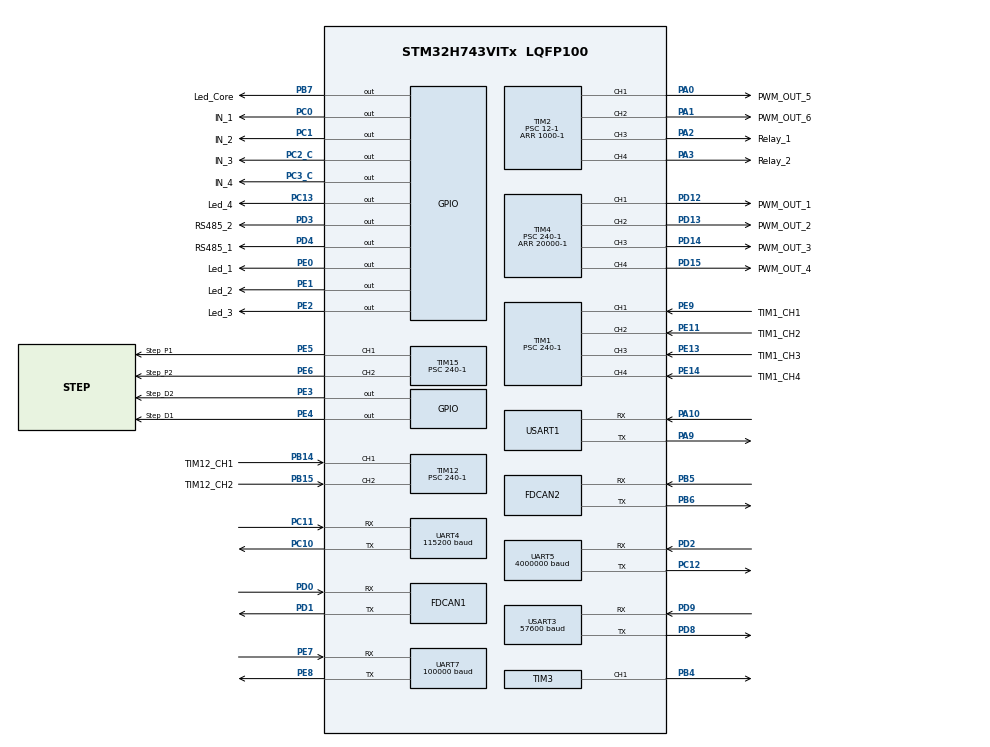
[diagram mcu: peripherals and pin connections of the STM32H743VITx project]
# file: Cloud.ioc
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CORTEX_M7.AccessPermission-Cortex_Memory_Protection_Unit_Region0_Settings=MPU_REGION_FULL_ACCESS
CORTEX_M7.BaseAddress-Cortex_Memory_Protection_Unit_Region0_Settings=0x24000000
CORTEX_M7.CPU_DCache=Enabled
CORTEX_M7.CPU_ICache=Enabled
CORTEX_M7.Enable-Cortex_Memory_Protection_Unit_Region0_Settings=MPU_REGION_ENABLE
CORTEX_M7.MPU_Control=MPU_PRIVILEGED_DEFAULT
CORTEX_M7.Size-Cortex_Memory_Protection_Unit_Region0_Settings=MPU_REGION_SIZE_256KB
CORTEX_M7.TypeExtField-Cortex_Memory_Protection_Unit_Region0_Settings=MPU_TEX_LEVEL1
Dma.Request0=UART4_RX
Dma.Request1=UART4_TX
Dma.Request2=UART5_RX
Dma.Request3=UART5_TX
Dma.Request4=USART3_RX
Dma.Request5=USART3_TX
Dma.Request6=TIM3_CH1
Dma.Request7=UART7_RX
Dma.Request8=USART1_RX
Dma.Request9=USART1_TX
Dma.TIM3_CH1.6.Direction=DMA_MEMORY_TO_PERIPH
Dma.TIM3_CH1.6.EventEnable=DISABLE
Dma.TIM3_CH1.6.FIFOMode=DMA_FIFOMODE_DISABLE
Dma.TIM3_CH1.6.Instance=DMA1_Stream6
Dma.TIM3_CH1.6.MemDataAlignment=DMA_MDATAALIGN_WORD
Dma.TIM3_CH1.6.MemInc=DMA_MINC_ENABLE
Dma.TIM3_CH1.6.Mode=DMA_NORMAL
Dma.TIM3_CH1.6.PeriphDataAlignment=DMA_PDATAALIGN_WORD
Dma.TIM3_CH1.6.PeriphInc=DMA_PINC_DISABLE
Dma.TIM3_CH1.6.Polarity=HAL_DMAMUX_REQ_GEN_RISING
Dma.TIM3_CH1.6.Priority=DMA_PRIORITY_LOW
Dma.TIM3_CH1.6.RequestNumber=1
Dma.TIM3_CH1.6.SignalID=NONE
Dma.TIM3_CH1.6.SyncEnable=DISABLE
Dma.TIM3_CH1.6.SyncPolarity=HAL_DMAMUX_SYNC_NO_EVENT
Dma.TIM3_CH1.6.SyncRequestNumber=1
Dma.TIM3_CH1.6.SyncSignalID=NONE
Dma.UART4_RX.0.Direction=DMA_PERIPH_TO_MEMORY
Dma.UART4_RX.0.EventEnable=DISABLE
Dma.UART4_RX.0.FIFOMode=DMA_FIFOMODE_DISABLE
Dma.UART4_RX.0.Instance=DMA1_Stream0
Dma.UART4_RX.0.MemDataAlignment=DMA_MDATAALIGN_BYTE
Dma.UART4_RX.0.MemInc=DMA_MINC_ENABLE
Dma.UART4_RX.0.Mode=DMA_CIRCULAR
Dma.UART4_RX.0.PeriphDataAlignment=DMA_PDATAALIGN_BYTE
Dma.UART4_RX.0.PeriphInc=DMA_PINC_DISABLE
Dma.UART4_RX.0.Polarity=HAL_DMAMUX_REQ_GEN_RISING
Dma.UART4_RX.0.Priority=DMA_PRIORITY_LOW
Dma.UART4_RX.0.RequestNumber=1
Dma.UART4_RX.0.SignalID=NONE
Dma.UART4_RX.0.SyncEnable=DISABLE
Dma.UART4_RX.0.SyncPolarity=HAL_DMAMUX_SYNC_NO_EVENT
Dma.UART4_RX.0.SyncRequestNumber=1
Dma.UART4_RX.0.SyncSignalID=NONE
Dma.UART4_TX.1.Direction=DMA_MEMORY_TO_PERIPH
Dma.UART4_TX.1.EventEnable=DISABLE
Dma.UART4_TX.1.FIFOMode=DMA_FIFOMODE_DISABLE
Dma.UART4_TX.1.Instance=DMA1_Stream1
Dma.UART4_TX.1.MemDataAlignment=DMA_MDATAALIGN_BYTE
Dma.UART4_TX.1.MemInc=DMA_MINC_ENABLE
Dma.UART4_TX.1.Mode=DMA_NORMAL
Dma.UART4_TX.1.PeriphDataAlignment=DMA_PDATAALIGN_BYTE
Dma.UART4_TX.1.PeriphInc=DMA_PINC_DISABLE
Dma.UART4_TX.1.Polarity=HAL_DMAMUX_REQ_GEN_RISING
Dma.UART4_TX.1.Priority=DMA_PRIORITY_LOW
Dma.UART4_TX.1.RequestNumber=1
Dma.UART4_TX.1.SignalID=NONE
Dma.UART4_TX.1.SyncEnable=DISABLE
Dma.UART4_TX.1.SyncPolarity=HAL_DMAMUX_SYNC_NO_EVENT
Dma.UART4_TX.1.SyncRequestNumber=1
Dma.UART4_TX.1.SyncSignalID=NONE
Dma.UART5_RX.2.Direction=DMA_PERIPH_TO_MEMORY
Dma.UART5_RX.2.EventEnable=DISABLE
Dma.UART5_RX.2.FIFOMode=DMA_FIFOMODE_DISABLE
Dma.UART5_RX.2.Instance=DMA1_Stream2
Dma.UART5_RX.2.MemDataAlignment=DMA_MDATAALIGN_BYTE
Dma.UART5_RX.2.MemInc=DMA_MINC_ENABLE
Dma.UART5_RX.2.Mode=DMA_CIRCULAR
Dma.UART5_RX.2.PeriphDataAlignment=DMA_PDATAALIGN_BYTE
Dma.UART5_RX.2.PeriphInc=DMA_PINC_DISABLE
Dma.UART5_RX.2.Polarity=HAL_DMAMUX_REQ_GEN_RISING
Dma.UART5_RX.2.Priority=DMA_PRIORITY_LOW
Dma.UART5_RX.2.RequestNumber=1
Dma.UART5_RX.2.SignalID=NONE
Dma.UART5_RX.2.SyncEnable=DISABLE
Dma.UART5_RX.2.SyncPolarity=HAL_DMAMUX_SYNC_NO_EVENT
Dma.UART5_RX.2.SyncRequestNumber=1
Dma.UART5_RX.2.SyncSignalID=NONE
Dma.UART5_TX.3.Direction=DMA_MEMORY_TO_PERIPH
Dma.UART5_TX.3.EventEnable=DISABLE
Dma.UART5_TX.3.FIFOMode=DMA_FIFOMODE_DISABLE
Dma.UART5_TX.3.Instance=DMA1_Stream3
Dma.UART5_TX.3.MemDataAlignment=DMA_MDATAALIGN_BYTE
Dma.UART5_TX.3.MemInc=DMA_MINC_ENABLE
Dma.UART5_TX.3.Mode=DMA_NORMAL
Dma.UART5_TX.3.PeriphDataAlignment=DMA_PDATAALIGN_BYTE
Dma.UART5_TX.3.PeriphInc=DMA_PINC_DISABLE
Dma.UART5_TX.3.Polarity=HAL_DMAMUX_REQ_GEN_RISING
Dma.UART5_TX.3.Priority=DMA_PRIORITY_LOW
Dma.UART5_TX.3.RequestNumber=1
Dma.UART5_TX.3.SignalID=NONE
Dma.UART5_TX.3.SyncEnable=DISABLE
Dma.UART5_TX.3.SyncPolarity=HAL_DMAMUX_SYNC_NO_EVENT
Dma.UART5_TX.3.SyncRequestNumber=1
Dma.UART5_TX.3.SyncSignalID=NONE
Dma.UART7_RX.7.Direction=DMA_PERIPH_TO_MEMORY
Dma.UART7_RX.7.EventEnable=DISABLE
Dma.UART7_RX.7.FIFOMode=DMA_FIFOMODE_DISABLE
Dma.UART7_RX.7.Instance=DMA1_Stream7
Dma.UART7_RX.7.MemDataAlignment=DMA_MDATAALIGN_BYTE
Dma.UART7_RX.7.MemInc=DMA_MINC_ENABLE
Dma.UART7_RX.7.Mode=DMA_CIRCULAR
Dma.UART7_RX.7.PeriphDataAlignment=DMA_PDATAALIGN_BYTE
Dma.UART7_RX.7.PeriphInc=DMA_PINC_DISABLE
Dma.UART7_RX.7.Polarity=HAL_DMAMUX_REQ_GEN_RISING
Dma.UART7_RX.7.Priority=DMA_PRIORITY_LOW
Dma.UART7_RX.7.RequestNumber=1
Dma.UART7_RX.7.SignalID=NONE
Dma.UART7_RX.7.SyncEnable=DISABLE
Dma.UART7_RX.7.SyncPolarity=HAL_DMAMUX_SYNC_NO_EVENT
Dma.UART7_RX.7.SyncRequestNumber=1
Dma.UART7_RX.7.SyncSignalID=NONE
Dma.USART1_RX.8.Direction=DMA_PERIPH_TO_MEMORY
Dma.USART1_RX.8.EventEnable=DISABLE
Dma.USART1_RX.8.FIFOMode=DMA_FIFOMODE_DISABLE
Dma.USART1_RX.8.Instance=DMA2_Stream0
Dma.USART1_RX.8.MemDataAlignment=DMA_MDATAALIGN_BYTE
Dma.USART1_RX.8.MemInc=DMA_MINC_ENABLE
Dma.USART1_RX.8.Mode=DMA_CIRCULAR
Dma.USART1_RX.8.PeriphDataAlignment=DMA_PDATAALIGN_BYTE
Dma.USART1_RX.8.PeriphInc=DMA_PINC_DISABLE
Dma.USART1_RX.8.Polarity=HAL_DMAMUX_REQ_GEN_RISING
Dma.USART1_RX.8.Priority=DMA_PRIORITY_LOW
Dma.USART1_RX.8.RequestNumber=1
Dma.USART1_RX.8.SignalID=NONE
Dma.USART1_RX.8.SyncEnable=DISABLE
Dma.USART1_RX.8.SyncPolarity=HAL_DMAMUX_SYNC_NO_EVENT
Dma.USART1_RX.8.SyncRequestNumber=1
Dma.USART1_RX.8.SyncSignalID=NONE
Dma.USART1_TX.9.Direction=DMA_MEMORY_TO_PERIPH
Dma.USART1_TX.9.EventEnable=DISABLE
Dma.USART1_TX.9.FIFOMode=DMA_FIFOMODE_DISABLE
Dma.USART1_TX.9.Instance=DMA2_Stream1
Dma.USART1_TX.9.MemDataAlignment=DMA_MDATAALIGN_BYTE
Dma.USART1_TX.9.MemInc=DMA_MINC_ENABLE
Dma.USART1_TX.9.Mode=DMA_NORMAL
Dma.USART1_TX.9.PeriphDataAlignment=DMA_PDATAALIGN_BYTE
Dma.USART1_TX.9.PeriphInc=DMA_PINC_DISABLE
Dma.USART1_TX.9.Polarity=HAL_DMAMUX_REQ_GEN_RISING
Dma.USART1_TX.9.Priority=DMA_PRIORITY_LOW
Dma.USART1_TX.9.RequestNumber=1
Dma.USART1_TX.9.SignalID=NONE
Dma.USART1_TX.9.SyncEnable=DISABLE
Dma.USART1_TX.9.SyncPolarity=HAL_DMAMUX_SYNC_NO_EVENT
Dma.USART1_TX.9.SyncRequestNumber=1
Dma.USART1_TX.9.SyncSignalID=NONE
Dma.USART3_RX.4.Direction=DMA_PERIPH_TO_MEMORY
Dma.USART3_RX.4.EventEnable=DISABLE
Dma.USART3_RX.4.FIFOMode=DMA_FIFOMODE_DISABLE
Dma.USART3_RX.4.Instance=DMA1_Stream4
Dma.USART3_RX.4.MemDataAlignment=DMA_MDATAALIGN_BYTE
Dma.USART3_RX.4.MemInc=DMA_MINC_ENABLE
Dma.USART3_RX.4.Mode=DMA_CIRCULAR
Dma.USART3_RX.4.PeriphDataAlignment=DMA_PDATAALIGN_BYTE
Dma.USART3_RX.4.PeriphInc=DMA_PINC_DISABLE
Dma.USART3_RX.4.Polarity=HAL_DMAMUX_REQ_GEN_RISING
Dma.USART3_RX.4.Priority=DMA_PRIORITY_LOW
Dma.USART3_RX.4.RequestNumber=1
Dma.USART3_RX.4.SignalID=NONE
Dma.USART3_RX.4.SyncEnable=DISABLE
Dma.USART3_RX.4.SyncPolarity=HAL_DMAMUX_SYNC_NO_EVENT
Dma.USART3_RX.4.SyncRequestNumber=1
Dma.USART3_RX.4.SyncSignalID=NONE
Dma.USART3_TX.5.Direction=DMA_MEMORY_TO_PERIPH
Dma.USART3_TX.5.EventEnable=DISABLE
Dma.USART3_TX.5.FIFOMode=DMA_FIFOMODE_DISABLE
Dma.USART3_TX.5.Instance=DMA1_Stream5
Dma.USART3_TX.5.MemDataAlignment=DMA_MDATAALIGN_BYTE
Dma.USART3_TX.5.MemInc=DMA_MINC_ENABLE
Dma.USART3_TX.5.Mode=DMA_NORMAL
Dma.USART3_TX.5.PeriphDataAlignment=DMA_PDATAALIGN_BYTE
Dma.USART3_TX.5.PeriphInc=DMA_PINC_DISABLE
Dma.USART3_TX.5.Polarity=HAL_DMAMUX_REQ_GEN_RISING
Dma.USART3_TX.5.Priority=DMA_PRIORITY_LOW
Dma.USART3_TX.5.RequestNumber=1
Dma.USART3_TX.5.SignalID=NONE
Dma.USART3_TX.5.SyncEnable=DISABLE
Dma.USART3_TX.5.SyncPolarity=HAL_DMAMUX_SYNC_NO_EVENT
Dma.USART3_TX.5.SyncRequestNumber=1
Dma.USART3_TX.5.SyncSignalID=NONE
FDCAN1.DataTimeSeg1=31
FDCAN1.DataTimeSeg2=8
FDCAN1.ExtFiltersNbr=32
FDCAN1.NominalSyncJumpWidth=2
FDCAN1.NominalTimeSeg1=31
FDCAN1.NominalTimeSeg2=8
FDCAN1.ProtocolException=ENABLE
FDCAN1.RxBuffersNbr=32
FDCAN1.RxFifo0ElmtsNbr=32
FDCAN1.StdFiltersNbr=32
FDCAN1.TxFifoQueueElmtsNbr=32
FDCAN2.DataTimeSeg1=31
FDCAN2.DataTimeSeg2=8
FDCAN2.ExtFiltersNbr=32
FDCAN2.MessageRAMOffset=1280
FDCAN2.NominalSyncJumpWidth=2
FDCAN2.NominalTimeSeg1=31
FDCAN2.NominalTimeSeg2=8
FDCAN2.ProtocolException=ENABLE
FDCAN2.RxBuffersNbr=32
FDCAN2.RxFifo1ElmtsNbr=32
FDCAN2.StdFiltersNbr=32
FDCAN2.TxFifoQueueElmtsNbr=32
Mcu.Family=STM32H7
Mcu.Name=STM32H743VITx
Mcu.Package=LQFP100
NVIC.DMA1_Stream0_IRQn=true\:4\:0\:true\:false\:true\:false\:true
NVIC.DMA1_Stream1_IRQn=true\:4\:0\:true\:false\:true\:false\:true
NVIC.DMA1_Stream2_IRQn=true\:4\:0\:true\:false\:true\:false\:true
NVIC.DMA1_Stream3_IRQn=true\:4\:0\:true\:false\:true\:false\:true
NVIC.DMA1_Stream4_IRQn=true\:4\:0\:true\:false\:true\:false\:true
NVIC.DMA1_Stream5_IRQn=true\:4\:0\:true\:false\:true\:false\:true
NVIC.DMA1_Stream6_IRQn=true\:5\:0\:true\:false\:true\:false\:true
NVIC.DMA1_Stream7_IRQn=true\:4\:0\:true\:false\:true\:false\:true
NVIC.DMA2_Stream0_IRQn=true\:0\:0\:false\:false\:true\:false\:true
NVIC.DMA2_Stream1_IRQn=true\:0\:0\:false\:false\:true\:false\:true
NVIC.FDCAN1_IT0_IRQn=true\:4\:0\:true\:false\:true\:true\:true
NVIC.FDCAN2_IT0_IRQn=true\:4\:0\:true\:false\:true\:true\:true
NVIC.PriorityGroup=NVIC_PRIORITYGROUP_4
NVIC.TIM1_CC_IRQn=true\:5\:0\:true\:false\:true\:true\:true
NVIC.TIM6_DAC_IRQn=true\:7\:0\:true\:false\:true\:true\:true
NVIC.TIM8_BRK_TIM12_IRQn=true\:6\:0\:true\:false\:true\:true\:true
NVIC.UART4_IRQn=true\:5\:0\:true\:false\:true\:true\:true
NVIC.UART5_IRQn=true\:5\:0\:true\:false\:true\:true\:true
NVIC.UART7_IRQn=true\:5\:0\:true\:false\:true\:true\:true
NVIC.USART1_IRQn=true\:5\:0\:true\:false\:true\:true\:true
NVIC.USART3_IRQn=true\:5\:0\:true\:false\:true\:true\:true
PA0.GPIO_Label=PWM_OUT_5
PA0.Signal=S_TIM2_CH1_ETR
PA1.GPIO_Label=PWM_OUT_6
PA1.Signal=S_TIM2_CH2
PA10.Mode=Asynchronous
PA10.Signal=USART1_RX
PA13\ (JTMS/SWDIO).Mode=Serial_Wire
PA13\ (JTMS/SWDIO).Signal=DEBUG_JTMS-SWDIO
PA14\ (JTCK/SWCLK).Mode=Serial_Wire
PA14\ (JTCK/SWCLK).Signal=DEBUG_JTCK-SWCLK
PA2.GPIO_Label=Relay_1
PA2.Signal=S_TIM2_CH3
PA3.GPIO_Label=Relay_2
PA3.Signal=S_TIM2_CH4
PA9.Mode=Asynchronous
PA9.Signal=USART1_TX
PB14.GPIO_Label=TIM12_CH1
PB14.Signal=S_TIM12_CH1
PB15.GPIO_Label=TIM12_CH2
PB15.Signal=S_TIM12_CH2
PB4\ (NJTRST).Signal=S_TIM3_CH1
PB5.Mode=FDCAN_Activate
PB5.Signal=FDCAN2_RX
PB6.Mode=FDCAN_Activate
PB6.Signal=FDCAN2_TX
PB7.GPIO_Label=Led_Core
PB7.Signal=GPIO_Output
PC0.GPIO_Label=IN_1
PC0.Signal=GPIO_Output
PC1.GPIO_Label=IN_2
PC1.Signal=GPIO_Output
PC10.Mode=Asynchronous
PC10.Signal=UART4_TX
PC11.Mode=Asynchronous
PC11.Signal=UART4_RX
PC12.Mode=Asynchronous
PC12.Signal=UART5_TX
PC13.GPIO_Label=Led_4
PC13.Signal=GPIO_Output
PC14-OSC32_IN\ (OSC32_IN).Mode=LSE-External-Oscillator
PC14-OSC32_IN\ (OSC32_IN).Signal=RCC_OSC32_IN
PC15-OSC32_OUT\ (OSC32_OUT).Mode=LSE-External-Oscillator
PC15-OSC32_OUT\ (OSC32_OUT).Signal=RCC_OSC32_OUT
PC2_C.GPIO_Label=IN_3
PC2_C.Signal=GPIO_Output
PC3_C.GPIO_Label=IN_4
PC3_C.Signal=GPIO_Output
PD0.Mode=FDCAN_Activate
PD0.Signal=FDCAN1_RX
PD1.Mode=FDCAN_Activate
PD1.Signal=FDCAN1_TX
PD12.GPIO_Label=PWM_OUT_1
PD12.Signal=S_TIM4_CH1
PD13.GPIO_Label=PWM_OUT_2
PD13.Signal=S_TIM4_CH2
PD14.GPIO_Label=PWM_OUT_3
PD14.Signal=S_TIM4_CH3
PD15.GPIO_Label=PWM_OUT_4
PD15.Signal=S_TIM4_CH4
PD2.Mode=Asynchronous
PD2.Signal=UART5_RX
PD3.GPIO_Label=RS485_2
PD3.PinState=GPIO_PIN_RESET
PD3.Signal=GPIO_Output
PD4.GPIO_Label=RS485_1
PD4.PinState=GPIO_PIN_RESET
PD4.Signal=GPIO_Output
PD8.Mode=Asynchronous
PD8.Signal=USART3_TX
PD9.Mode=Asynchronous
PD9.Signal=USART3_RX
PE0.GPIO_Label=Led_1
PE0.Signal=GPIO_Output
PE1.GPIO_Label=Led_2
PE1.Signal=GPIO_Output
PE11.GPIO_Label=TIM1_CH2
PE11.Signal=S_TIM1_CH2
PE13.GPIO_Label=TIM1_CH3
PE13.Signal=S_TIM1_CH3
PE14.GPIO_Label=TIM1_CH4
PE14.Signal=S_TIM1_CH4
PE2.GPIO_Label=Led_3
PE2.Signal=GPIO_Output
PE3.GPIO_Label=Step_D2
PE3.PinState=GPIO_PIN_RESET
PE3.Signal=GPIO_Output
PE4.GPIO_Label=Step_D1
PE4.PinState=GPIO_PIN_RESET
PE4.Signal=GPIO_Output
PE5.GPIO_Label=Step_P1
PE5.Signal=S_TIM15_CH1
PE6.GPIO_Label=Step_P2
PE6.Signal=S_TIM15_CH2
PE7.Mode=Asynchronous
PE7.Signal=UART7_RX
PE8.Mode=Asynchronous
PE8.Signal=UART7_TX
PE9.GPIO_Label=TIM1_CH1
PE9.Signal=S_TIM1_CH1
PH0-OSC_IN\ (PH0).Mode=HSE-External-Oscillator
PH0-OSC_IN\ (PH0).Signal=RCC_OSC_IN
PH1-OSC_OUT\ (PH1).Mode=HSE-External-Oscillator
PH1-OSC_OUT\ (PH1).Signal=RCC_OSC_OUT
ProjectManager.HeapSize=0x200
ProjectManager.StackSize=0x400
ProjectManager.TargetToolchain=MDK-ARM V5.32
RCC.ADCFreq_Value=480000000
RCC.APB1Freq_Value=120000000
RCC.APB2Freq_Value=120000000
RCC.APB3Freq_Value=120000000
RCC.APB4Freq_Value=120000000
RCC.CortexFreq_Value=480000000
RCC.D1PPRE=RCC_APB3_DIV2
RCC.D2PPRE1=RCC_APB1_DIV2
RCC.D2PPRE2=RCC_APB2_DIV2
RCC.D3PPRE=RCC_APB4_DIV2
RCC.DIVM1=2
RCC.DIVM2=2
RCC.DIVN1=240
RCC.DIVN2=240
RCC.DIVQ1=24
RCC.DIVQ2=24
RCC.HCLKFreq_Value=240000000
RCC.HPRE=RCC_HCLK_DIV2
RCC.HSE_VALUE=8000000
RCC.PLLFRACN=0
RCC.PLLSourceVirtual=RCC_PLLSOURCE_HSE
RCC.SYSCLKFreq_VALUE=480000000
RCC.SYSCLKSource=RCC_SYSCLKSOURCE_PLLCLK
RCC.USBFreq_Value=40000000
SH.S_TIM12_CH1.0=TIM12_CH1,Input_Capture1_from_TI1
SH.S_TIM12_CH2.0=TIM12_CH2,Input_Capture2_from_TI2
SH.S_TIM15_CH1.0=TIM15_CH1,PWM Generation1 CH1
SH.S_TIM15_CH2.0=TIM15_CH2,PWM Generation2 CH2
SH.S_TIM1_CH1.0=TIM1_CH1,Input_Capture1_from_TI1
SH.S_TIM1_CH2.0=TIM1_CH2,Input_Capture2_from_TI2
SH.S_TIM1_CH3.0=TIM1_CH3,Input_Capture3_from_TI3
SH.S_TIM1_CH4.0=TIM1_CH4,Input_Capture4_from_TI4
SH.S_TIM2_CH1_ETR.0=TIM2_CH1,PWM Generation1 CH1
SH.S_TIM2_CH2.0=TIM2_CH2,PWM Generation2 CH2
SH.S_TIM2_CH3.0=TIM2_CH3,PWM Generation3 CH3
SH.S_TIM2_CH4.0=TIM2_CH4,PWM Generation4 CH4
SH.S_TIM3_CH1.0=TIM3_CH1,PWM Generation1 CH1
SH.S_TIM4_CH1.0=TIM4_CH1,PWM Generation1 CH1
SH.S_TIM4_CH2.0=TIM4_CH2,PWM Generation2 CH2
SH.S_TIM4_CH3.0=TIM4_CH3,PWM Generation3 CH3
SH.S_TIM4_CH4.0=TIM4_CH4,PWM Generation4 CH4
TIM1.Channel-Input_Capture1_from_TI1=TIM_CHANNEL_1
TIM1.Channel-Input_Capture2_from_TI2=TIM_CHANNEL_2
TIM1.Channel-Input_Capture3_from_TI3=TIM_CHANNEL_3
TIM1.Channel-Input_Capture4_from_TI4=TIM_CHANNEL_4
TIM1.ICPolarity_CH1=TIM_INPUTCHANNELPOLARITY_BOTHEDGE
TIM1.ICPolarity_CH2=TIM_INPUTCHANNELPOLARITY_BOTHEDGE
TIM1.ICPolarity_CH3=TIM_INPUTCHANNELPOLARITY_BOTHEDGE
TIM1.ICPolarity_CH4=TIM_INPUTCHANNELPOLARITY_BOTHEDGE
TIM1.Prescaler=240-1
TIM12.Channel-Input_Capture1_from_TI1=TIM_CHANNEL_1
TIM12.Channel-Input_Capture2_from_TI2=TIM_CHANNEL_2
TIM12.ICPolarity_CH1=TIM_INPUTCHANNELPOLARITY_BOTHEDGE
TIM12.ICPolarity_CH2=TIM_INPUTCHANNELPOLARITY_BOTHEDGE
TIM12.Prescaler=240-1
TIM15.Channel-PWM\ Generation1\ CH1=TIM_CHANNEL_1
TIM15.Channel-PWM\ Generation2\ CH2=TIM_CHANNEL_2
TIM15.Period=10000-1
TIM15.Prescaler=240-1
TIM2.Channel-PWM\ Generation1\ CH1=TIM_CHANNEL_1
TIM2.Channel-PWM\ Generation2\ CH2=TIM_CHANNEL_2
TIM2.Channel-PWM\ Generation3\ CH3=TIM_CHANNEL_3
TIM2.Channel-PWM\ Generation4\ CH4=TIM_CHANNEL_4
TIM2.Period=1000-1
TIM2.Prescaler=12-1
TIM3.Channel-PWM\ Generation1\ CH1=TIM_CHANNEL_1
TIM3.Period=4-1
TIM3.Prescaler=80-1
TIM4.Channel-PWM\ Generation1\ CH1=TIM_CHANNEL_1
TIM4.Channel-PWM\ Generation2\ CH2=TIM_CHANNEL_2
TIM4.Channel-PWM\ Generation3\ CH3=TIM_CHANNEL_3
TIM4.Channel-PWM\ Generation4\ CH4=TIM_CHANNEL_4
TIM4.Period=20000-1
TIM4.Prescaler=240-1
TIM6.Period=1000-1
TIM6.Prescaler=240-1
UART4.BaudRate=115200
UART5.BaudRate=4000000
UART7.BaudRate=100000
UART7.Parity=PARITY_EVEN
UART7.StopBits=UART_STOPBITS_2
UART7.WordLength=WORDLENGTH_9B
USART1.VirtualMode-Asynchronous=VM_ASYNC
USART3.BaudRate=57600
USART3.VirtualMode-Asynchronous=VM_ASYNC
VP_TIM12_VS_ClockSourceINT.Mode=Internal
VP_TIM15_VS_ClockSourceINT.Mode=Internal
VP_TIM1_VS_ClockSourceINT.Mode=Internal
VP_TIM2_VS_ClockSourceINT.Mode=Internal
VP_TIM3_VS_ClockSourceINT.Mode=Internal
VP_TIM4_VS_ClockSourceINT.Mode=Internal
VP_TIM6_VS_ClockSourceINT.Mode=Enable_Timer
board=custom

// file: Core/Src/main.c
/* USER CODE BEGIN Header */
/**
  ******************************************************************************
  * @file           : main.c
  * @brief          : Main program body
  ******************************************************************************
  * @attention
  *
  * Copyright (c) 2025 STMicroelectronics.
  * All rights reserved.
  *
  * This software is licensed under terms that can be found in the LICENSE file
  * in the root directory of this software component.
  * If no LICENSE file comes with this software, it is provided AS-IS.
  *
  ******************************************************************************
  */
/* USER CODE END Header */
#include "main.h"
#include "dma.h"
#include "fdcan.h"
#include "tim.h"
#include "usart.h"
#include "gpio.h"

void SystemClock_Config(void);
static void MPU_Config(void);

int main(void)
{

  /* MPU Configuration--------------------------------------------------------*/
  MPU_Config();

  /* Enable I-Cache---------------------------------------------------------*/
  SCB_EnableICache();

  /* Enable D-Cache---------------------------------------------------------*/
  SCB_EnableDCache();

  /* MCU Configuration--------------------------------------------------------*/

  /* Reset of all peripherals, Initializes the Flash interface and the Systick. */
  HAL_Init();

  /* USER CODE BEGIN Init */

	HAL_Delay(1000);//�ȴ�1S��ϵͳ����   ��ɾ

  /* USER CODE END Init */

  /* Configure the system clock */
  SystemClock_Config();

  /* Initialize all configured peripherals */
  MX_GPIO_Init();
  MX_DMA_Init();
  MX_TIM1_Init();
  MX_TIM6_Init();
  MX_TIM12_Init();
  MX_TIM15_Init();
  MX_TIM2_Init();
  MX_TIM4_Init();
  MX_FDCAN1_Init();
  MX_UART4_Init();
  MX_FDCAN2_Init();
  MX_UART5_Init();
  MX_USART3_UART_Init();
  MX_TIM3_Init();
  MX_UART7_Init();
  MX_USART1_UART_Init();
  /* USER CODE BEGIN 2 */
   Mymain();

  /* USER CODE END 2 */

  /* Infinite loop */
  while (1)
  {

  }
}

void SystemClock_Config(void)
{
  RCC_OscInitTypeDef RCC_OscInitStruct = {0};
  RCC_ClkInitTypeDef RCC_ClkInitStruct = {0};

  /** Supply configuration update enable
  */
  HAL_PWREx_ConfigSupply(PWR_LDO_SUPPLY);
  /** Configure the main internal regulator output voltage
  */
  __HAL_PWR_VOLTAGESCALING_CONFIG(PWR_REGULATOR_VOLTAGE_SCALE0);

  while(!__HAL_PWR_GET_FLAG(PWR_FLAG_VOSRDY)) {}
  /** Initializes the RCC Oscillators according to the specified parameters
  * in the RCC_OscInitTypeDef structure.
  */
  RCC_OscInitStruct.OscillatorType = RCC_OSCILLATORTYPE_HSE;
  RCC_OscInitStruct.HSEState = RCC_HSE_ON;
  RCC_OscInitStruct.PLL.PLLState = RCC_PLL_ON;
  RCC_OscInitStruct.PLL.PLLSource = RCC_PLLSOURCE_HSE;
  RCC_OscInitStruct.PLL.PLLM = 2;
  RCC_OscInitStruct.PLL.PLLN = 240;
  RCC_OscInitStruct.PLL.PLLP = 2;
  RCC_OscInitStruct.PLL.PLLQ = 24;
  RCC_OscInitStruct.PLL.PLLR = 2;
  RCC_OscInitStruct.PLL.PLLRGE = RCC_PLL1VCIRANGE_2;
  RCC_OscInitStruct.PLL.PLLVCOSEL = RCC_PLL1VCOWIDE;
  RCC_OscInitStruct.PLL.PLLFRACN = 0;
  if (HAL_RCC_OscConfig(&RCC_OscInitStruct) != HAL_OK)
  {
    Error_Handler();
  }
  /** Initializes the CPU, AHB and APB buses clocks
  */
  RCC_ClkInitStruct.ClockType = RCC_CLOCKTYPE_HCLK|RCC_CLOCKTYPE_SYSCLK
                              |RCC_CLOCKTYPE_PCLK1|RCC_CLOCKTYPE_PCLK2
                              |RCC_CLOCKTYPE_D3PCLK1|RCC_CLOCKTYPE_D1PCLK1;
  RCC_ClkInitStruct.SYSCLKSource = RCC_SYSCLKSOURCE_PLLCLK;
  RCC_ClkInitStruct.SYSCLKDivider = RCC_SYSCLK_DIV1;
  RCC_ClkInitStruct.AHBCLKDivider = RCC_HCLK_DIV2;
  RCC_ClkInitStruct.APB3CLKDivider = RCC_APB3_DIV2;
  RCC_ClkInitStruct.APB1CLKDivider = RCC_APB1_DIV2;
  RCC_ClkInitStruct.APB2CLKDivider = RCC_APB2_DIV2;
  RCC_ClkInitStruct.APB4CLKDivider = RCC_APB4_DIV2;

  if (HAL_RCC_ClockConfig(&RCC_ClkInitStruct, FLASH_LATENCY_4) != HAL_OK)
  {
    Error_Handler();
  }
}

/* MPU Configuration */

void MPU_Config(void)
{
  MPU_Region_InitTypeDef MPU_InitStruct = {0};

  /* Disables the MPU */
  HAL_MPU_Disable();
  /** Initializes and configures the Region and the memory to be protected
  */
  MPU_InitStruct.Enable = MPU_REGION_ENABLE;
  MPU_InitStruct.Number = MPU_REGION_NUMBER0;
  MPU_InitStruct.BaseAddress = 0x24000000;
  MPU_InitStruct.Size = MPU_REGION_SIZE_256KB;
  MPU_InitStruct.SubRegionDisable = 0x0;
  MPU_InitStruct.TypeExtField = MPU_TEX_LEVEL1;
  MPU_InitStruct.AccessPermission = MPU_REGION_FULL_ACCESS;
  MPU_InitStruct.DisableExec = MPU_INSTRUCTION_ACCESS_ENABLE;
  MPU_InitStruct.IsShareable = MPU_ACCESS_NOT_SHAREABLE;
  MPU_InitStruct.IsCacheable = MPU_ACCESS_NOT_CACHEABLE;
  MPU_InitStruct.IsBufferable = MPU_ACCESS_NOT_BUFFERABLE;

  HAL_MPU_ConfigRegion(&MPU_InitStruct);
  /* Enables the MPU */
  HAL_MPU_Enable(MPU_PRIVILEGED_DEFAULT);

}

void Error_Handler(void)
{
  __disable_irq();
  while (1)
  {
  }
}
